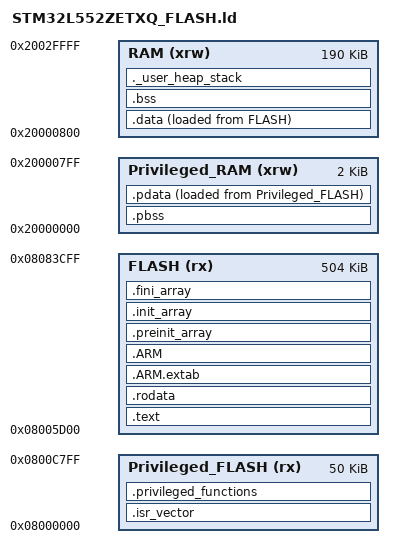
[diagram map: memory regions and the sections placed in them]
/*
******************************************************************************
**
**  File        : LinkerScript.ld
**
**  Author		: Auto-generated by STM32CubeIDE
**
**  Abstract    : Linker script for STM32L5x2xE Device from STM32L5 series
**                      512Kbytes ROM
**                      192Kbytes RAM
**
**                Set heap size, stack size and stack location according
**                to application requirements.
**
**                Set memory bank area and size if external memory is used.
**
**  Target      : STMicroelectronics STM32
**
**  Distribution: The file is distributed as is without any warranty
**                of any kind.
**
*****************************************************************************
** @attention
**
** <h2><center>&copy; Copyright (c) 2019 STMicroelectronics.
** All rights reserved.</center></h2>
**
** This software component is licensed by ST under Apache License, Version 2.0,
** the "License"; You may not use this file except in compliance with the
** License. You may obtain a copy of the License at:
**                        opensource.org/licenses/Apache-2.0
**
*****************************************************************************
*/

/* Entry Point */
ENTRY(Reset_Handler)

/* Highest address of the user mode stack */
_estack = ORIGIN(RAM) + LENGTH(RAM);	/* end of "RAM" Ram type memory */
/* Generate a link error if heap and stack don't fit into RAM */
_Min_Heap_Size = 0x200;      /* required amount of heap  */
_Min_Stack_Size = 0x400; /* required amount of stack */

/* Specify the memory areas */
MEMORY
{
FLASH (rx)      : ORIGIN = 0x08005D00, LENGTH = 504K
Privileged_FLASH (rx)      : ORIGIN = 0x08000000, LENGTH = 50K
RAM (xrw)      : ORIGIN = 0x20000800, LENGTH = 190K
Privileged_RAM (xrw)      : ORIGIN = 0x20000000, LENGTH = 2K
}

/* Variables used by FreeRTOS-MPU. */
_Privileged_Functions_Region_Size = 7K;
_Privileged_Data_Region_Size = 2K;

__FLASH_segment_start__ = ORIGIN( Privileged_FLASH );
__FLASH_segment_end__ = __FLASH_segment_start__ + LENGTH( Privileged_FLASH ) + LENGTH( FLASH );

__privileged_functions_start__ = ORIGIN( Privileged_FLASH );
__privileged_functions_end__ = __privileged_functions_start__ + _Privileged_Functions_Region_Size;

__unprivileged_flash_start__ = 0x08001F00;
__unprivileged_flash_end__   =  0x0807FFFF;

__SRAM_segment_start__ = ORIGIN( Privileged_RAM );
__SRAM_segment_end__ = __SRAM_segment_start__ + LENGTH( Privileged_RAM ) + LENGTH( RAM );

__privileged_sram_start__ = ORIGIN( Privileged_RAM );
__privileged_sram_end__ = __SRAM_segment_start__ + LENGTH( Privileged_RAM );

__unprivileged_sram_start__    =  0x20000800;
__unprivileged_sram_end__      =  0x2002FFFF;

__privileged_data_start__ = ORIGIN( Privileged_RAM );
__privileged_data_end__ = __privileged_data_start__ + _Privileged_Data_Region_Size;

__syscalls_flash_start__       =  0x08001D00;
__syscalls_flash_end__         =  0x08001EFF;


/* Define output sections */
SECTIONS
{
  /* The startup code goes first into FLASH */
  .isr_vector :
  {
    . = ALIGN(4);
    KEEP(*(.isr_vector)) /* Startup code */
    . = ALIGN(4);
  } >Privileged_FLASH
  
    .privileged_functions : 
  {
    . = ALIGN(4);
    *(privileged_functions)
    *(privileged_functions*)
    . = ALIGN(4);
  } >Privileged_FLASH

  /* The program code and other data goes into FLASH */
  .text :
  {
    . = ALIGN(4);
    *(.text)           /* .text sections (code) */
    *(.text*)          /* .text* sections (code) */
    *(.glue_7)         /* glue arm to thumb code */
    *(.glue_7t)        /* glue thumb to arm code */
    *(.eh_frame)

    KEEP (*(.init))
    KEEP (*(.fini))

    . = ALIGN(4);
    _etext = .;        /* define a global symbols at end of code */
  } >FLASH

  /* Constant data goes into FLASH */
  .rodata :
  {
    . = ALIGN(4);
    *(.rodata)         /* .rodata sections (constants, strings, etc.) */
    *(.rodata*)        /* .rodata* sections (constants, strings, etc.) */
    . = ALIGN(4);
  } >FLASH

  .ARM.extab   : { *(.ARM.extab* .gnu.linkonce.armextab.*) } >FLASH
  .ARM : {
    __exidx_start = .;
    *(.ARM.exidx*)
    __exidx_end = .;
  } >FLASH

  .preinit_array     :
  {
    PROVIDE_HIDDEN (__preinit_array_start = .);
    KEEP (*(.preinit_array*))
    PROVIDE_HIDDEN (__preinit_array_end = .);
  } >FLASH
  .init_array :
  {
    PROVIDE_HIDDEN (__init_array_start = .);
    KEEP (*(SORT(.init_array.*)))
    KEEP (*(.init_array*))
    PROVIDE_HIDDEN (__init_array_end = .);
  } >FLASH
  .fini_array :
  {
    PROVIDE_HIDDEN (__fini_array_start = .);
    KEEP (*(SORT(.fini_array.*)))
    KEEP (*(.fini_array*))
    PROVIDE_HIDDEN (__fini_array_end = .);
  } >FLASH

.pbss : 
  {
    . = ALIGN(4);
    _spbss = .;
    *(privileged_data)
    *(privileged_data*)
    . = ALIGN(4);
    _epbss = .;
  } >Privileged_RAM
  
  /* used by the startup to initialize data */
  _sipdata = LOADADDR(.pdata);

  .pdata : 
  {
    . = ALIGN(4);
    _spdata = .;
    *(privileged_initialized_data)
    *(privileged_initialized_data*)
    . = ALIGN(4);
    _epdata = .;
  } >Privileged_RAM AT> Privileged_FLASH

  /* used by the startup to initialize data */
  _sidata = LOADADDR(.data);

  /* Initialized data sections goes into RAM, load LMA copy after code */
  .data : 
  {
    . = ALIGN(4);
    _sdata = .;        /* create a global symbol at data start */
    *(.data)           /* .data sections */
    *(.data*)          /* .data* sections */

    . = ALIGN(4);
    _edata = .;        /* define a global symbol at data end */
  } >RAM AT> FLASH

 
  /* Uninitialized data section */
  . = ALIGN(4);
  .bss :
  {
    /* This is used by the startup in order to initialize the .bss section */
    _sbss = .;         /* define a global symbol at bss start */
    __bss_start__ = _sbss;
    *(.bss)
    *(.bss*)
    *(COMMON)

    . = ALIGN(4);
    _ebss = .;         /* define a global symbol at bss end */
    __bss_end__ = _ebss;
  } >RAM

  /* User_heap_stack section, used to check that there is enough RAM left */
  ._user_heap_stack :
  {
    . = ALIGN(8);
    PROVIDE ( end = . );
    PROVIDE ( _end = . );
    . = . + _Min_Heap_Size;
    . = . + _Min_Stack_Size;
    . = ALIGN(8);
  } >RAM

  

  /* Remove information from the standard libraries */
  /DISCARD/ :
  {
    libc.a ( * )
    libm.a ( * )
    libgcc.a ( * )
  }

  .ARM.attributes 0 : { *(.ARM.attributes) }
}
